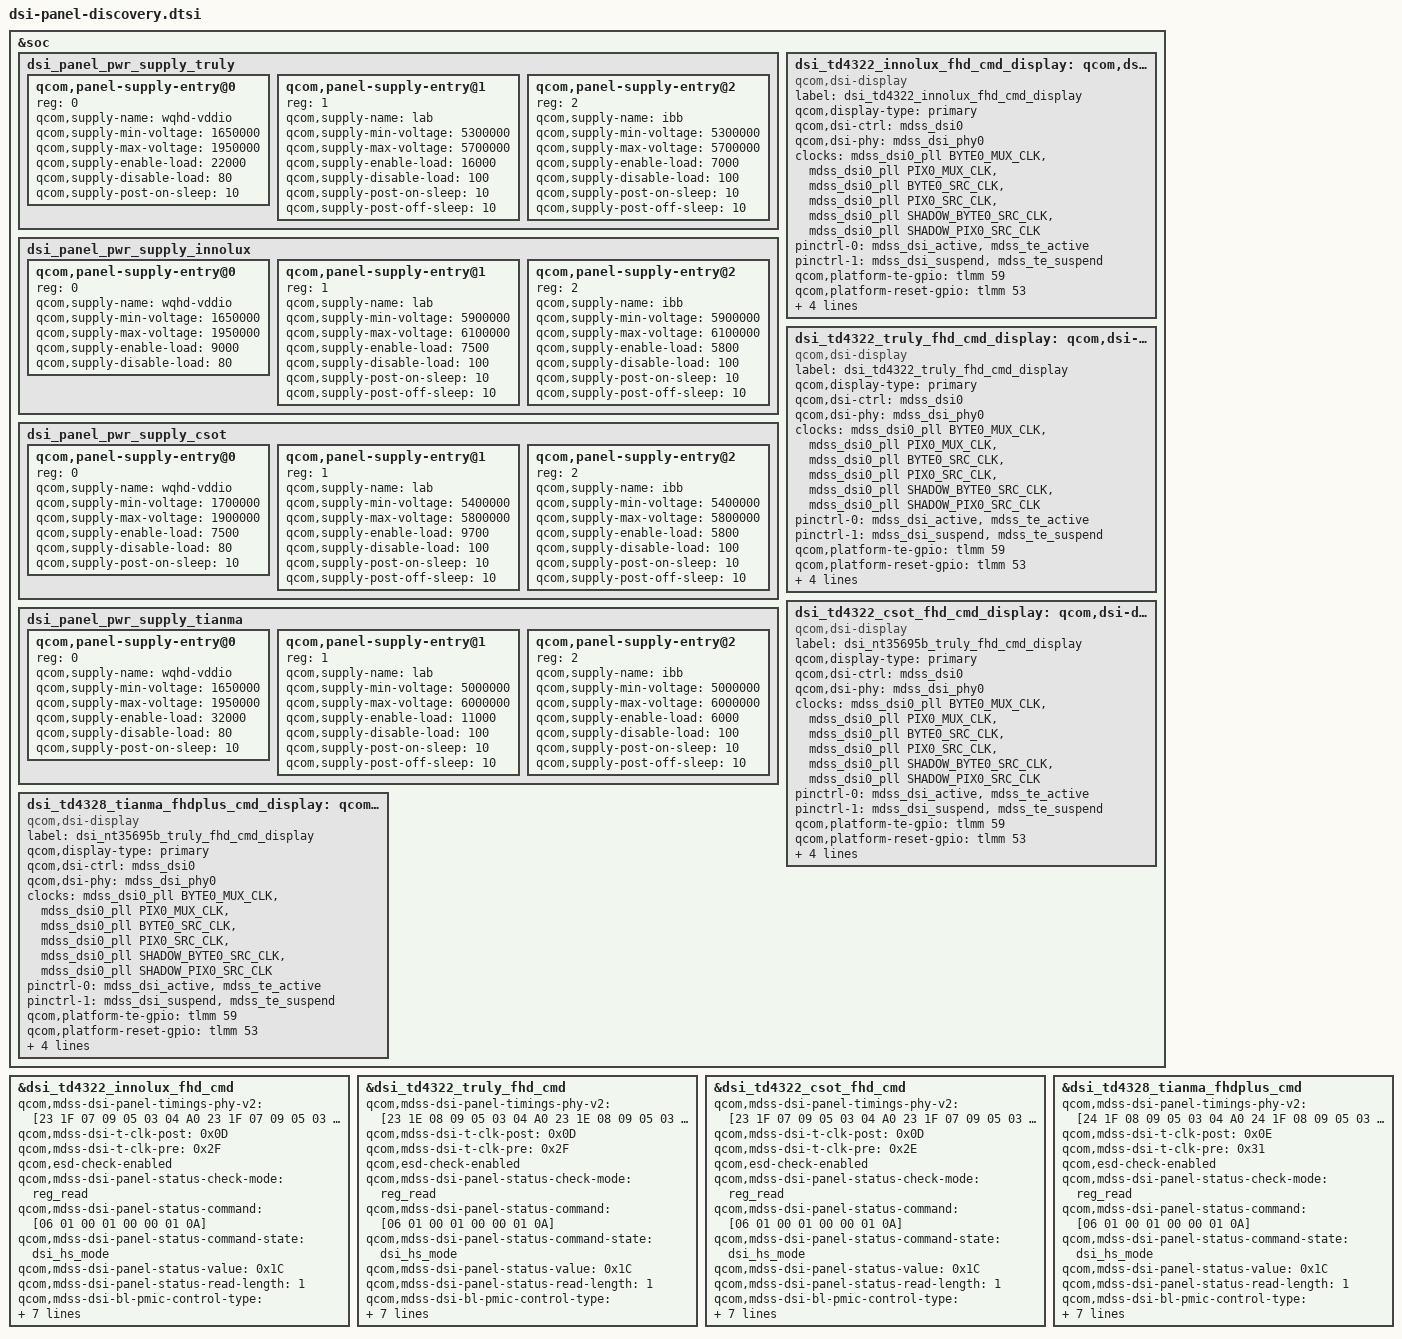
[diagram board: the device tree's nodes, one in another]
/* Copyright (c) 2019, The Linux Foundation. All rights reserved.
 * Copyright (c) 2019, Pavel Dubrova <pashadubrova@gmail.com>
 *
 * This program is free software; you can redistribute it and/or modify
 * it under the terms of the GNU General Public License version 2 and
 * only version 2 as published by the Free Software Foundation.
 *
 * This program is distributed in the hope that it will be useful,
 * but WITHOUT ANY WARRANTY; without even the implied warranty of
 * MERCHANTABILITY or FITNESS FOR A PARTICULAR PURPOSE.  See the
 * GNU General Public License for more details.
 */
 
#include "dsi-panel-td4322-innolux-fhd-cmd.dtsi"
#include "dsi-panel-td4322-truly-fhd-cmd.dtsi"
#include "dsi-panel-td4322-csot-fhd-cmd.dtsi"
#include "dsi-panel-td4328-tianma-fhdplus-cmd.dtsi"

&soc {
	dsi_panel_pwr_supply_truly: dsi_panel_pwr_supply_truly {
		#address-cells = <1>;
		#size-cells = <0>;

		qcom,panel-supply-entry@0 {
			reg = <0>;
			qcom,supply-name = "wqhd-vddio";
			qcom,supply-min-voltage = <1650000>;
			qcom,supply-max-voltage = <1950000>;
			qcom,supply-enable-load = <22000>;
			qcom,supply-disable-load = <80>;
			qcom,supply-post-on-sleep = <10>;
		};

		qcom,panel-supply-entry@1 {
			reg = <1>;
			qcom,supply-name = "lab";
			qcom,supply-min-voltage = <5300000>;
			qcom,supply-max-voltage = <5700000>;
			qcom,supply-enable-load = <16000>;
			qcom,supply-disable-load = <100>;
			qcom,supply-post-on-sleep = <10>;
			qcom,supply-post-off-sleep = <10>;
		};

		qcom,panel-supply-entry@2 {
			reg = <2>;
			qcom,supply-name = "ibb";
			qcom,supply-min-voltage = <5300000>;
			qcom,supply-max-voltage = <5700000>;
			qcom,supply-enable-load = <7000>;
			qcom,supply-disable-load = <100>;
			qcom,supply-post-on-sleep = <10>;
			qcom,supply-post-off-sleep = <10>;
		};
	};

	dsi_panel_pwr_supply_innolux: dsi_panel_pwr_supply_innolux {
		#address-cells = <1>;
		#size-cells = <0>;

		qcom,panel-supply-entry@0 {
			reg = <0>;
			qcom,supply-name = "wqhd-vddio";
			qcom,supply-min-voltage = <1650000>;
			qcom,supply-max-voltage = <1950000>;
			qcom,supply-enable-load = <9000>;
			qcom,supply-disable-load = <80>;
		};

		qcom,panel-supply-entry@1 {
			reg = <1>;
			qcom,supply-name = "lab";
			qcom,supply-min-voltage = <5900000>;
			qcom,supply-max-voltage = <6100000>;
			qcom,supply-enable-load = <7500>;
			qcom,supply-disable-load = <100>;
			qcom,supply-post-on-sleep = <10>;
			qcom,supply-post-off-sleep = <10>;
		};

		qcom,panel-supply-entry@2 {
			reg = <2>;
			qcom,supply-name = "ibb";
			qcom,supply-min-voltage = <5900000>;
			qcom,supply-max-voltage = <6100000>;
			qcom,supply-enable-load = <5800>;
			qcom,supply-disable-load = <100>;
			qcom,supply-post-on-sleep = <10>;
			qcom,supply-post-off-sleep = <10>;
		};
	};

	dsi_panel_pwr_supply_csot: dsi_panel_pwr_supply_csot {
		#address-cells = <1>;
		#size-cells = <0>;

		qcom,panel-supply-entry@0 {
			reg = <0>;
			qcom,supply-name = "wqhd-vddio";
			qcom,supply-min-voltage = <1700000>;
			qcom,supply-max-voltage = <1900000>;
			qcom,supply-enable-load = <7500>;
			qcom,supply-disable-load = <80>;
			qcom,supply-post-on-sleep = <10>;
		};

		qcom,panel-supply-entry@1 {
			reg = <1>;
			qcom,supply-name = "lab";
			qcom,supply-min-voltage = <5400000>;
			qcom,supply-max-voltage = <5800000>;
			qcom,supply-enable-load = <9700>;
			qcom,supply-disable-load = <100>;
			qcom,supply-post-on-sleep = <10>;
			qcom,supply-post-off-sleep = <10>;
		};

		qcom,panel-supply-entry@2 {
			reg = <2>;
			qcom,supply-name = "ibb";
			qcom,supply-min-voltage = <5400000>;
			qcom,supply-max-voltage = <5800000>;
			qcom,supply-enable-load = <5800>;
			qcom,supply-disable-load = <100>;
			qcom,supply-post-on-sleep = <10>;
			qcom,supply-post-off-sleep = <10>;
		};
	};

	/* SM42 TD4328 Tianma FHD+ CMD */
	dsi_panel_pwr_supply_tianma: dsi_panel_pwr_supply_tianma {
		#address-cells = <1>;
		#size-cells = <0>;

		qcom,panel-supply-entry@0 {
			reg = <0>;
			qcom,supply-name = "wqhd-vddio";
			qcom,supply-min-voltage = <1650000>;
			qcom,supply-max-voltage = <1950000>;
			qcom,supply-enable-load = <32000>;
			qcom,supply-disable-load = <80>;
			qcom,supply-post-on-sleep = <10>;
		};

		qcom,panel-supply-entry@1 {
			reg = <1>;
			qcom,supply-name = "lab";
			qcom,supply-min-voltage = <5000000>;
			qcom,supply-max-voltage = <6000000>;
			qcom,supply-enable-load = <11000>;
			qcom,supply-disable-load = <100>;
			qcom,supply-post-on-sleep = <10>;
			qcom,supply-post-off-sleep = <10>;
		};

		qcom,panel-supply-entry@2 {
			reg = <2>;
			qcom,supply-name = "ibb";
			qcom,supply-min-voltage = <5000000>;
			qcom,supply-max-voltage = <6000000>;
			qcom,supply-enable-load = <6000>;
			qcom,supply-disable-load = <100>;
			qcom,supply-post-on-sleep = <10>;
			qcom,supply-post-off-sleep = <10>;
		};
	};

	dsi_td4322_innolux_fhd_cmd_display: qcom,dsi-display@0 {
		compatible = "qcom,dsi-display";
		label = "dsi_td4322_innolux_fhd_cmd_display";
		qcom,display-type = "primary";

		qcom,dsi-ctrl = <&mdss_dsi0>;
		qcom,dsi-phy = <&mdss_dsi_phy0>;

		clocks = <&mdss_dsi0_pll BYTE0_MUX_CLK>,
				 <&mdss_dsi0_pll PIX0_MUX_CLK>,
				 <&mdss_dsi0_pll BYTE0_SRC_CLK>,
				 <&mdss_dsi0_pll PIX0_SRC_CLK>,
				 <&mdss_dsi0_pll SHADOW_BYTE0_SRC_CLK>,
				 <&mdss_dsi0_pll SHADOW_PIX0_SRC_CLK>;
		clock-names = "mux_byte_clk", "mux_pixel_clk",
				"src_byte_clk", "src_pixel_clk",
				"shadow_byte_clk", "shadow_pixel_clk";

		pinctrl-names = "panel_active", "panel_suspend";
		pinctrl-0 = <&mdss_dsi_active &mdss_te_active>;
		pinctrl-1 = <&mdss_dsi_suspend &mdss_te_suspend>;
		qcom,platform-te-gpio = <&tlmm 59 0>;
		qcom,platform-reset-gpio = <&tlmm 53 0>;

		qcom,dsi-panel = <&dsi_td4322_innolux_fhd_cmd>;
		vddio-supply = <&pm660_l11>;
		lab-supply = <&lcdb_ldo_vreg>;
		ibb-supply = <&lcdb_ncp_vreg>;
	};

	dsi_td4322_truly_fhd_cmd_display: qcom,dsi-display@1 {
		compatible = "qcom,dsi-display";
		label = "dsi_td4322_truly_fhd_cmd_display";
		qcom,display-type = "primary";

		qcom,dsi-ctrl = <&mdss_dsi0>;
		qcom,dsi-phy = <&mdss_dsi_phy0>;

		clocks = <&mdss_dsi0_pll BYTE0_MUX_CLK>,
				 <&mdss_dsi0_pll PIX0_MUX_CLK>,
				 <&mdss_dsi0_pll BYTE0_SRC_CLK>,
				 <&mdss_dsi0_pll PIX0_SRC_CLK>,
				 <&mdss_dsi0_pll SHADOW_BYTE0_SRC_CLK>,
				 <&mdss_dsi0_pll SHADOW_PIX0_SRC_CLK>;
		clock-names = "mux_byte_clk", "mux_pixel_clk",
				"src_byte_clk", "src_pixel_clk",
				"shadow_byte_clk", "shadow_pixel_clk";

		pinctrl-names = "panel_active", "panel_suspend";
		pinctrl-0 = <&mdss_dsi_active &mdss_te_active>;
		pinctrl-1 = <&mdss_dsi_suspend &mdss_te_suspend>;
		qcom,platform-te-gpio = <&tlmm 59 0>;
		qcom,platform-reset-gpio = <&tlmm 53 0>;

		qcom,dsi-panel = <&dsi_td4322_truly_fhd_cmd>;
		vddio-supply = <&pm660_l11>;
		lab-supply = <&lcdb_ldo_vreg>;
		ibb-supply = <&lcdb_ncp_vreg>;
	};

	dsi_td4322_csot_fhd_cmd_display: qcom,dsi-display@2 {
		compatible = "qcom,dsi-display";
		label = "dsi_nt35695b_truly_fhd_cmd_display";
		qcom,display-type = "primary";

		qcom,dsi-ctrl = <&mdss_dsi0>;
		qcom,dsi-phy = <&mdss_dsi_phy0>;

		clocks = <&mdss_dsi0_pll BYTE0_MUX_CLK>,
				 <&mdss_dsi0_pll PIX0_MUX_CLK>,
				 <&mdss_dsi0_pll BYTE0_SRC_CLK>,
				 <&mdss_dsi0_pll PIX0_SRC_CLK>,
				 <&mdss_dsi0_pll SHADOW_BYTE0_SRC_CLK>,
				 <&mdss_dsi0_pll SHADOW_PIX0_SRC_CLK>;
		clock-names = "mux_byte_clk", "mux_pixel_clk",
				"src_byte_clk", "src_pixel_clk",
				"shadow_byte_clk", "shadow_pixel_clk";

		pinctrl-names = "panel_active", "panel_suspend";
		pinctrl-0 = <&mdss_dsi_active &mdss_te_active>;
		pinctrl-1 = <&mdss_dsi_suspend &mdss_te_suspend>;
		qcom,platform-te-gpio = <&tlmm 59 0>;
		qcom,platform-reset-gpio = <&tlmm 53 0>;

		qcom,dsi-panel = <&dsi_td4322_csot_fhd_cmd>;
		vddio-supply = <&pm660_l11>;
		lab-supply = <&lcdb_ldo_vreg>;
		ibb-supply = <&lcdb_ncp_vreg>;
	};

	dsi_td4328_tianma_fhdplus_cmd_display: qcom,dsi-display@3 {
		compatible = "qcom,dsi-display";
		label = "dsi_nt35695b_truly_fhd_cmd_display";
		qcom,display-type = "primary";

		qcom,dsi-ctrl = <&mdss_dsi0>;
		qcom,dsi-phy = <&mdss_dsi_phy0>;

		clocks = <&mdss_dsi0_pll BYTE0_MUX_CLK>,
				 <&mdss_dsi0_pll PIX0_MUX_CLK>,
				 <&mdss_dsi0_pll BYTE0_SRC_CLK>,
				 <&mdss_dsi0_pll PIX0_SRC_CLK>,
				 <&mdss_dsi0_pll SHADOW_BYTE0_SRC_CLK>,
				 <&mdss_dsi0_pll SHADOW_PIX0_SRC_CLK>;
		clock-names = "mux_byte_clk", "mux_pixel_clk",
				"src_byte_clk", "src_pixel_clk",
				"shadow_byte_clk", "shadow_pixel_clk";

		pinctrl-names = "panel_active", "panel_suspend";
		pinctrl-0 = <&mdss_dsi_active &mdss_te_active>;
		pinctrl-1 = <&mdss_dsi_suspend &mdss_te_suspend>;
		qcom,platform-te-gpio = <&tlmm 59 0>;
		qcom,platform-reset-gpio = <&tlmm 53 0>;

		qcom,dsi-panel = <&dsi_td4328_tianma_fhdplus_cmd>;
		vddio-supply = <&pm660_l11>;
		lab-supply = <&lcdb_ldo_vreg>;
		ibb-supply = <&lcdb_ncp_vreg>;
	};
};

&dsi_td4322_innolux_fhd_cmd {
	qcom,mdss-dsi-panel-timings-phy-v2 = [23 1F 07 09 05 03 04 A0
					      23 1F 07 09 05 03 04 A0
					      23 1F 07 09 05 03 04 A0
					      23 1F 07 09 05 03 04 A0
					      23 1A 08 09 05 03 04 A0];
	qcom,mdss-dsi-t-clk-post = <0x0D>;
	qcom,mdss-dsi-t-clk-pre = <0x2F>;

	qcom,esd-check-enabled;
	qcom,mdss-dsi-panel-status-check-mode = "reg_read";
	qcom,mdss-dsi-panel-status-command = [06 01 00 01 00 00 01 0A];
	qcom,mdss-dsi-panel-status-command-state = "dsi_hs_mode";
	qcom,mdss-dsi-panel-status-value = <0x1C>;
	qcom,mdss-dsi-panel-status-read-length = <1>;
	qcom,mdss-dsi-bl-pmic-control-type = "bl_ctrl_wled";
	qcom,mdss-dsi-bl-min-level = <1>;
	qcom,mdss-dsi-bl-max-level = <4095>;
	qcom,panel-supply-entries = <&dsi_panel_pwr_supply_innolux>;
	qcom,platform-te-gpio = <&tlmm 59 0>;
	qcom,platform-reset-gpio = <&tlmm 53 0>;
};

&dsi_td4322_truly_fhd_cmd {
	qcom,mdss-dsi-panel-timings-phy-v2 = [23 1E 08 09 05 03 04 A0
					      23 1E 08 09 05 03 04 A0
					      23 1E 08 09 05 03 04 A0
					      23 1E 08 09 05 03 04 A0
					      23 1A 08 09 05 03 04 A0];
	qcom,mdss-dsi-t-clk-post = <0x0D>;
	qcom,mdss-dsi-t-clk-pre = <0x2F>;
	qcom,esd-check-enabled;
	qcom,mdss-dsi-panel-status-check-mode = "reg_read";
	qcom,mdss-dsi-panel-status-command = [06 01 00 01 00 00 01 0A];
	qcom,mdss-dsi-panel-status-command-state = "dsi_hs_mode";
	qcom,mdss-dsi-panel-status-value = <0x1C>;
	qcom,mdss-dsi-panel-status-read-length = <1>;
	qcom,mdss-dsi-bl-pmic-control-type = "bl_ctrl_wled";
	qcom,mdss-dsi-bl-min-level = <1>;
	qcom,mdss-dsi-bl-max-level = <4095>;
	qcom,panel-supply-entries = <&dsi_panel_pwr_supply_truly>;
	qcom,platform-te-gpio = <&tlmm 59 0>;
	qcom,platform-reset-gpio = <&tlmm 53 0>;
};

&dsi_td4322_csot_fhd_cmd {
	qcom,mdss-dsi-panel-timings-phy-v2 = [23 1F 07 09 05 03 04 A0
					      23 1F 07 09 05 03 04 A0
					      23 1F 07 09 05 03 04 A0
					      23 1F 07 09 05 03 04 A0
					      23 19 08 08 05 03 04 A0];
	qcom,mdss-dsi-t-clk-post = <0x0D>;
	qcom,mdss-dsi-t-clk-pre = <0x2E>;
	qcom,esd-check-enabled;
	qcom,mdss-dsi-panel-status-check-mode = "reg_read";
	qcom,mdss-dsi-panel-status-command = [06 01 00 01 00 00 01 0A];
	qcom,mdss-dsi-panel-status-command-state = "dsi_hs_mode";
	qcom,mdss-dsi-panel-status-value = <0x1C>;
	qcom,mdss-dsi-panel-status-read-length = <1>;
	qcom,mdss-dsi-bl-pmic-control-type = "bl_ctrl_wled";
	qcom,mdss-dsi-bl-min-level = <1>;
	qcom,mdss-dsi-bl-max-level = <4095>;
	qcom,panel-supply-entries = <&dsi_panel_pwr_supply_csot>;
	qcom,platform-te-gpio = <&tlmm 59 0>;
	qcom,platform-reset-gpio = <&tlmm 53 0>;
};

&dsi_td4328_tianma_fhdplus_cmd {
	qcom,mdss-dsi-panel-timings-phy-v2 = [24 1F 08 09 05 03 04 A0
					      24 1F 08 09 05 03 04 A0
					      24 1F 08 09 05 03 04 A0
					      24 1F 08 09 05 03 04 A0
					      24 1C 08 09 05 03 04 A0];
	qcom,mdss-dsi-t-clk-post = <0x0E>;
	qcom,mdss-dsi-t-clk-pre = <0x31>;
	qcom,esd-check-enabled;
	qcom,mdss-dsi-panel-status-check-mode = "reg_read";
	qcom,mdss-dsi-panel-status-command = [06 01 00 01 00 00 01 0A];
	qcom,mdss-dsi-panel-status-command-state = "dsi_hs_mode";
	qcom,mdss-dsi-panel-status-value = <0x1C>;
	qcom,mdss-dsi-panel-status-read-length = <1>;
	qcom,mdss-dsi-bl-pmic-control-type = "bl_ctrl_wled";
	qcom,mdss-dsi-bl-min-level = <1>;
	qcom,mdss-dsi-bl-max-level = <4095>;
	qcom,panel-supply-entries = <&dsi_panel_pwr_supply_tianma>;
	qcom,platform-te-gpio = <&tlmm 59 0>;
	qcom,platform-reset-gpio = <&tlmm 53 0>;
};
